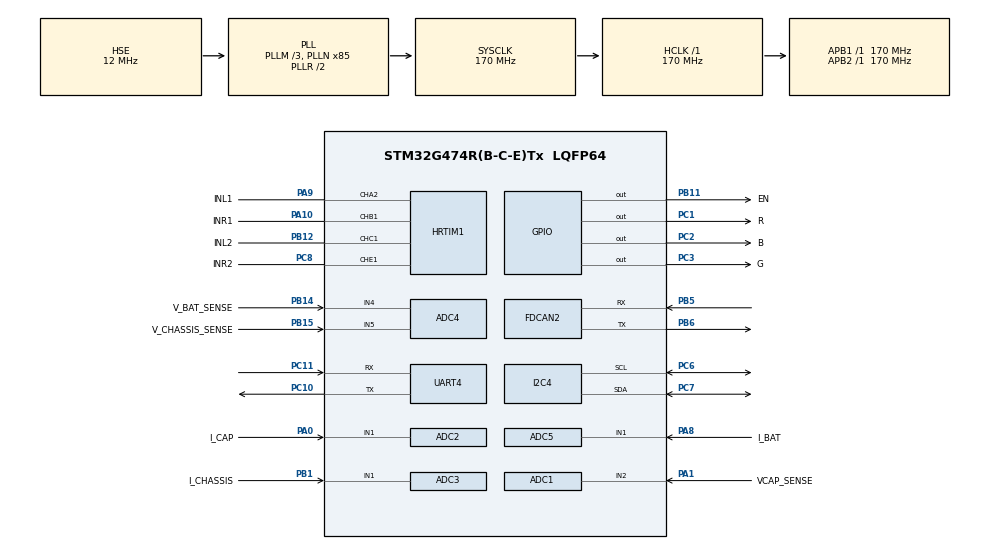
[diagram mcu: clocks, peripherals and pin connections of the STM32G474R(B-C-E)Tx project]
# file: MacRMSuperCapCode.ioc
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ADC1.Channel-0\#ChannelRegularConversion=ADC_CHANNEL_2
ADC1.ContinuousConvMode=DISABLE
ADC1.DMAContinuousRequests=ENABLE
ADC1.ExternalTrigConv=ADC_EXTERNALTRIG_HRTIM_TRG1
ADC1.NbrOfConversion=1
ADC1.NbrOfConversionFlag=1
ADC1.OffsetNumber-0\#ChannelRegularConversion=ADC_OFFSET_NONE
ADC1.Rank-0\#ChannelRegularConversion=1
ADC1.SamplingTime-0\#ChannelRegularConversion=ADC_SAMPLETIME_24CYCLES_5
ADC1.master=1
ADC2.Channel-3\#ChannelRegularConversion=ADC_CHANNEL_1
ADC2.DMAContinuousRequests=ENABLE
ADC2.ExternalTrigConv=ADC_EXTERNALTRIG_HRTIM_TRG1
ADC2.NbrOfConversionFlag=1
ADC2.OffsetNumber-3\#ChannelRegularConversion=ADC_OFFSET_NONE
ADC2.Rank-3\#ChannelRegularConversion=1
ADC2.SamplingTime-3\#ChannelRegularConversion=ADC_SAMPLETIME_24CYCLES_5
ADC3.Channel-0\#ChannelRegularConversion=ADC_CHANNEL_1
ADC3.DMAContinuousRequests=ENABLE
ADC3.ExternalTrigConv=ADC_EXTERNALTRIG_HRTIM_TRG1
ADC3.NbrOfConversionFlag=1
ADC3.OffsetNumber-0\#ChannelRegularConversion=ADC_OFFSET_NONE
ADC3.Rank-0\#ChannelRegularConversion=1
ADC3.SamplingTime-0\#ChannelRegularConversion=ADC_SAMPLETIME_24CYCLES_5
ADC3.master=1
ADC4.Channel-0\#ChannelRegularConversion=ADC_CHANNEL_5
ADC4.Channel-1\#ChannelRegularConversion=ADC_CHANNEL_4
ADC4.ContinuousConvMode=DISABLE
ADC4.DMAContinuousRequests=ENABLE
ADC4.DiscontinuousConvMode=ENABLE
ADC4.EOCSelection=ADC_EOC_SEQ_CONV
ADC4.ExternalTrigConv=ADC_EXTERNALTRIG_HRTIM_TRG1
ADC4.NbrOfConversion=2
ADC4.NbrOfConversionFlag=1
ADC4.NbrOfDiscConversion=2
ADC4.OffsetNumber-0\#ChannelRegularConversion=ADC_OFFSET_NONE
ADC4.OffsetNumber-1\#ChannelRegularConversion=ADC_OFFSET_NONE
ADC4.Rank-0\#ChannelRegularConversion=1
ADC4.Rank-1\#ChannelRegularConversion=2
ADC4.SamplingTime-0\#ChannelRegularConversion=ADC_SAMPLETIME_24CYCLES_5
ADC4.SamplingTime-1\#ChannelRegularConversion=ADC_SAMPLETIME_24CYCLES_5
ADC5.Channel-2\#ChannelRegularConversion=ADC_CHANNEL_1
ADC5.DMAContinuousRequests=ENABLE
ADC5.EOCSelection=ADC_EOC_SEQ_CONV
ADC5.ExternalTrigConv=ADC_EXTERNALTRIG_HRTIM_TRG1
ADC5.NbrOfConversion=1
ADC5.NbrOfConversionFlag=1
ADC5.OffsetNumber-2\#ChannelRegularConversion=ADC_OFFSET_NONE
ADC5.Rank-2\#ChannelRegularConversion=1
ADC5.SamplingTime-2\#ChannelRegularConversion=ADC_SAMPLETIME_24CYCLES_5
Dma.ADC1.0.Direction=DMA_PERIPH_TO_MEMORY
Dma.ADC1.0.EventEnable=DISABLE
Dma.ADC1.0.Instance=DMA1_Channel1
Dma.ADC1.0.MemDataAlignment=DMA_MDATAALIGN_HALFWORD
Dma.ADC1.0.MemInc=DMA_MINC_ENABLE
Dma.ADC1.0.Mode=DMA_CIRCULAR
Dma.ADC1.0.PeriphDataAlignment=DMA_PDATAALIGN_HALFWORD
Dma.ADC1.0.PeriphInc=DMA_PINC_DISABLE
Dma.ADC1.0.Polarity=HAL_DMAMUX_REQ_GEN_RISING
Dma.ADC1.0.Priority=DMA_PRIORITY_LOW
Dma.ADC1.0.RequestNumber=1
Dma.ADC1.0.SignalID=NONE
Dma.ADC1.0.SyncEnable=DISABLE
Dma.ADC1.0.SyncPolarity=HAL_DMAMUX_SYNC_NO_EVENT
Dma.ADC1.0.SyncRequestNumber=1
Dma.ADC1.0.SyncSignalID=NONE
Dma.ADC2.1.Direction=DMA_PERIPH_TO_MEMORY
Dma.ADC2.1.EventEnable=DISABLE
Dma.ADC2.1.Instance=DMA1_Channel2
Dma.ADC2.1.MemDataAlignment=DMA_MDATAALIGN_HALFWORD
Dma.ADC2.1.MemInc=DMA_MINC_ENABLE
Dma.ADC2.1.Mode=DMA_CIRCULAR
Dma.ADC2.1.PeriphDataAlignment=DMA_PDATAALIGN_HALFWORD
Dma.ADC2.1.PeriphInc=DMA_PINC_DISABLE
Dma.ADC2.1.Polarity=HAL_DMAMUX_REQ_GEN_RISING
Dma.ADC2.1.Priority=DMA_PRIORITY_LOW
Dma.ADC2.1.RequestNumber=1
Dma.ADC2.1.SignalID=NONE
Dma.ADC2.1.SyncEnable=DISABLE
Dma.ADC2.1.SyncPolarity=HAL_DMAMUX_SYNC_NO_EVENT
Dma.ADC2.1.SyncRequestNumber=1
Dma.ADC2.1.SyncSignalID=NONE
Dma.ADC3.2.Direction=DMA_PERIPH_TO_MEMORY
Dma.ADC3.2.EventEnable=DISABLE
Dma.ADC3.2.Instance=DMA1_Channel3
Dma.ADC3.2.MemDataAlignment=DMA_MDATAALIGN_HALFWORD
Dma.ADC3.2.MemInc=DMA_MINC_ENABLE
Dma.ADC3.2.Mode=DMA_CIRCULAR
Dma.ADC3.2.PeriphDataAlignment=DMA_PDATAALIGN_HALFWORD
Dma.ADC3.2.PeriphInc=DMA_PINC_DISABLE
Dma.ADC3.2.Polarity=HAL_DMAMUX_REQ_GEN_RISING
Dma.ADC3.2.Priority=DMA_PRIORITY_LOW
Dma.ADC3.2.RequestNumber=1
Dma.ADC3.2.SignalID=NONE
Dma.ADC3.2.SyncEnable=DISABLE
Dma.ADC3.2.SyncPolarity=HAL_DMAMUX_SYNC_NO_EVENT
Dma.ADC3.2.SyncRequestNumber=1
Dma.ADC3.2.SyncSignalID=NONE
Dma.ADC4.3.Direction=DMA_PERIPH_TO_MEMORY
Dma.ADC4.3.EventEnable=DISABLE
Dma.ADC4.3.Instance=DMA1_Channel4
Dma.ADC4.3.MemDataAlignment=DMA_MDATAALIGN_HALFWORD
Dma.ADC4.3.MemInc=DMA_MINC_ENABLE
Dma.ADC4.3.Mode=DMA_CIRCULAR
Dma.ADC4.3.PeriphDataAlignment=DMA_PDATAALIGN_HALFWORD
Dma.ADC4.3.PeriphInc=DMA_PINC_DISABLE
Dma.ADC4.3.Polarity=HAL_DMAMUX_REQ_GEN_RISING
Dma.ADC4.3.Priority=DMA_PRIORITY_LOW
Dma.ADC4.3.RequestNumber=1
Dma.ADC4.3.SignalID=NONE
Dma.ADC4.3.SyncEnable=DISABLE
Dma.ADC4.3.SyncPolarity=HAL_DMAMUX_SYNC_NO_EVENT
Dma.ADC4.3.SyncRequestNumber=1
Dma.ADC4.3.SyncSignalID=NONE
Dma.ADC5.4.Direction=DMA_PERIPH_TO_MEMORY
Dma.ADC5.4.EventEnable=DISABLE
Dma.ADC5.4.Instance=DMA1_Channel5
Dma.ADC5.4.MemDataAlignment=DMA_MDATAALIGN_HALFWORD
Dma.ADC5.4.MemInc=DMA_MINC_ENABLE
Dma.ADC5.4.Mode=DMA_CIRCULAR
Dma.ADC5.4.PeriphDataAlignment=DMA_PDATAALIGN_HALFWORD
Dma.ADC5.4.PeriphInc=DMA_PINC_DISABLE
Dma.ADC5.4.Polarity=HAL_DMAMUX_REQ_GEN_RISING
Dma.ADC5.4.Priority=DMA_PRIORITY_LOW
Dma.ADC5.4.RequestNumber=1
Dma.ADC5.4.SignalID=NONE
Dma.ADC5.4.SyncEnable=DISABLE
Dma.ADC5.4.SyncPolarity=HAL_DMAMUX_SYNC_NO_EVENT
Dma.ADC5.4.SyncRequestNumber=1
Dma.ADC5.4.SyncSignalID=NONE
Dma.Request0=ADC1
Dma.Request1=ADC2
Dma.Request2=ADC3
Dma.Request3=ADC4
Dma.Request4=ADC5
Dma.Request5=UART4_TX
Dma.UART4_TX.5.Direction=DMA_MEMORY_TO_PERIPH
Dma.UART4_TX.5.EventEnable=DISABLE
Dma.UART4_TX.5.Instance=DMA1_Channel7
Dma.UART4_TX.5.MemDataAlignment=DMA_MDATAALIGN_BYTE
Dma.UART4_TX.5.MemInc=DMA_MINC_ENABLE
Dma.UART4_TX.5.Mode=DMA_NORMAL
Dma.UART4_TX.5.PeriphDataAlignment=DMA_PDATAALIGN_BYTE
Dma.UART4_TX.5.PeriphInc=DMA_PINC_DISABLE
Dma.UART4_TX.5.Polarity=HAL_DMAMUX_REQ_GEN_RISING
Dma.UART4_TX.5.Priority=DMA_PRIORITY_LOW
Dma.UART4_TX.5.RequestNumber=1
Dma.UART4_TX.5.SignalID=NONE
Dma.UART4_TX.5.SyncEnable=DISABLE
Dma.UART4_TX.5.SyncPolarity=HAL_DMAMUX_SYNC_NO_EVENT
Dma.UART4_TX.5.SyncRequestNumber=1
Dma.UART4_TX.5.SyncSignalID=NONE
FDCAN2.CalculateBaudRateNominal=1000000
FDCAN2.CalculateTimeBitNominal=1000
FDCAN2.CalculateTimeQuantumNominal=100.0
FDCAN2.DataPrescaler=17
FDCAN2.DataSyncJumpWidth=4
FDCAN2.DataTimeSeg1=5
FDCAN2.DataTimeSeg2=4
FDCAN2.ExtFiltersNbr=8
FDCAN2.NominalPrescaler=17
FDCAN2.NominalSyncJumpWidth=4
FDCAN2.NominalTimeSeg1=5
FDCAN2.NominalTimeSeg2=4
FDCAN2.StdFiltersNbr=28
HRTIM1.ADCTrigger1_Source1=HRTIM_ADCTRIGGEREVENT13_MASTER_PERIOD
HRTIM1.ADCTrigger_Id1=HRTIM_ADCTRIGGER_1
HRTIM1.BurstDMAconfig-MasterTimer=__NULL
HRTIM1.CompareUnit1-MasterTimer=HRTIM_COMPAREUNIT_1
HRTIM1.CompareUnit1-Output_TA2=HRTIM_COMPAREUNIT_1
HRTIM1.CompareUnit1-Output_TB1=HRTIM_COMPAREUNIT_1
HRTIM1.CompareUnit1-Output_TC1=HRTIM_COMPAREUNIT_1
HRTIM1.CompareUnit1-Output_TE1=HRTIM_COMPAREUNIT_1
HRTIM1.CompareUnit2-MasterTimer=HRTIM_COMPAREUNIT_2
HRTIM1.CompareUnit3-MasterTimer=HRTIM_COMPAREUNIT_3
HRTIM1.CompareUnit4-MasterTimer=HRTIM_COMPAREUNIT_4
HRTIM1.CompareValue1-MasterTimer=13600
HRTIM1.CompareValue2-MasterTimer=13600
HRTIM1.CompareValue3-MasterTimer=13600
HRTIM1.CompareValue4-MasterTimer=13600
HRTIM1.InterruptRequests1_Master=HRTIM_MASTER_IT_MREP
HRTIM1.ModeTimeBase-Output_TA2=HRTIM_MODE_SINGLESHOT_RETRIGGERABLE
HRTIM1.ModeTimeBase-Output_TB1=HRTIM_MODE_SINGLESHOT_RETRIGGERABLE
HRTIM1.ModeTimeBase-Output_TC1=HRTIM_MODE_SINGLESHOT_RETRIGGERABLE
HRTIM1.ModeTimeBase-Output_TE1=HRTIM_MODE_SINGLESHOT_RETRIGGERABLE
HRTIM1.NumberADCTriggerSource1=1
HRTIM1.NumberInterruptRequests_Master-MasterTimer=1
HRTIM1.NumberResetSource1-Output_TB1=1
HRTIM1.NumberResetSource1-Output_TC1=1
HRTIM1.NumberResetSource1-Output_TE1=1
HRTIM1.NumberResetSource2-Output_TA2=1
HRTIM1.NumberResetTrigger-Output_TA2=1
HRTIM1.NumberResetTrigger-Output_TB1=1
HRTIM1.NumberResetTrigger-Output_TC1=1
HRTIM1.NumberResetTrigger-Output_TE1=1
HRTIM1.NumberSetSource1-Output_TB1=1
HRTIM1.NumberSetSource1-Output_TC1=1
HRTIM1.NumberSetSource1-Output_TE1=1
HRTIM1.NumberSetSource2-Output_TA2=1
HRTIM1.Periode_MASTER=13600
HRTIM1.Periode_TA=27200
HRTIM1.Periode_TB=27200
HRTIM1.Periode_TC=27200
HRTIM1.Periode_TE=27200
HRTIM1.PreloadEnable-MasterTimer=HRTIM_PRELOAD_ENABLED
HRTIM1.PreloadEnable-Output_TA2=HRTIM_PRELOAD_ENABLED
HRTIM1.PreloadEnable-Output_TB1=HRTIM_PRELOAD_ENABLED
HRTIM1.PreloadEnable-Output_TC1=HRTIM_PRELOAD_ENABLED
HRTIM1.PreloadEnable-Output_TE1=HRTIM_PRELOAD_ENABLED
HRTIM1.PrescalerRatio_TA=HRTIM_PRESCALERRATIO_MUL32
HRTIM1.RepetitionUpdate-MasterTimer=HRTIM_UPDATEONREPETITION_ENABLED
HRTIM1.RepetitionUpdate-Output_TA2=HRTIM_UPDATEONREPETITION_ENABLED
HRTIM1.RepetitionUpdate-Output_TB1=HRTIM_UPDATEONREPETITION_ENABLED
HRTIM1.RepetitionUpdate-Output_TC1=HRTIM_UPDATEONREPETITION_ENABLED
HRTIM1.RepetitionUpdate-Output_TE1=HRTIM_UPDATEONREPETITION_ENABLED
HRTIM1.ResetOutput1_Source1-Output_TB1=HRTIM_OUTPUTRESET_TIMCMP1
HRTIM1.ResetOutput1_Source1-Output_TC1=HRTIM_OUTPUTRESET_TIMCMP1
HRTIM1.ResetOutput1_Source1-Output_TE1=HRTIM_OUTPUTRESET_TIMCMP1
HRTIM1.ResetOutput2_Source1-Output_TA2=HRTIM_OUTPUTRESET_TIMCMP1
HRTIM1.ResetTrigger1-Output_TA2=HRTIM_TIMRESETTRIGGER_MASTER_CMP1
HRTIM1.ResetTrigger1-Output_TB1=HRTIM_TIMRESETTRIGGER_MASTER_CMP2
HRTIM1.ResetTrigger1-Output_TC1=HRTIM_TIMRESETTRIGGER_MASTER_CMP3
HRTIM1.ResetTrigger1-Output_TE1=HRTIM_TIMRESETTRIGGER_MASTER_CMP4
HRTIM1.ResetUpdate-Output_TA2=HRTIM_TIMUPDATEONRESET_ENABLED
HRTIM1.ResetUpdate-Output_TB1=HRTIM_TIMUPDATEONRESET_ENABLED
HRTIM1.ResetUpdate-Output_TC1=HRTIM_TIMUPDATEONRESET_ENABLED
HRTIM1.ResetUpdate-Output_TE1=HRTIM_TIMUPDATEONRESET_ENABLED
HRTIM1.SetOutput1_Source1-Output_TB1=HRTIM_OUTPUTSET_MASTERCMP2
HRTIM1.SetOutput1_Source1-Output_TC1=HRTIM_OUTPUTSET_MASTERCMP3
HRTIM1.SetOutput1_Source1-Output_TE1=HRTIM_OUTPUTSET_MASTERCMP4
HRTIM1.SetOutput2_Source1-Output_TA2=HRTIM_OUTPUTSET_MASTERCMP1
I2C4.Timing=0x40B285C2
IWDG.Reload=2047
IWDG.Window=2047
Mcu.Family=STM32G4
Mcu.Name=STM32G474R(B-C-E)Tx
Mcu.Package=LQFP64
NVIC.FDCAN2_IT0_IRQn=true\:0\:0\:false\:false\:true\:true\:true\:true
NVIC.HRTIM1_Master_IRQn=true\:1\:0\:true\:false\:true\:true\:true\:true
NVIC.PriorityGroup=NVIC_PRIORITYGROUP_4
NVIC.UART4_IRQn=true\:0\:0\:false\:false\:true\:true\:true\:true
PA0.GPIO_Label=I_CAP
PA0.Mode=IN1-Single-Ended
PA0.Signal=ADC2_IN1
PA1.GPIO_Label=VCAP_SENSE
PA1.Mode=IN2-Single-Ended
PA1.Signal=ADC1_IN2
PA10.GPIO_Label=INR1
PA10.GPIO_Speed_High_Default=GPIO_SPEED_FREQ_MEDIUM
PA10.Mode=Output_TB1
PA10.Signal=HRTIM1_CHB1
PA13.Mode=Serial_Wire
PA13.Signal=SYS_JTMS-SWDIO
PA14.Mode=Serial_Wire
PA14.Signal=SYS_JTCK-SWCLK
PA8.GPIO_Label=I_BAT
PA8.Mode=IN1-Single-Ended
PA8.Signal=ADC5_IN1
PA9.GPIO_Label=INL1
PA9.GPIO_Speed_High_Default=GPIO_SPEED_FREQ_MEDIUM
PA9.Mode=Output_TA2
PA9.Signal=HRTIM1_CHA2
PB1.GPIO_Label=I_CHASSIS
PB1.Mode=IN1-Single-Ended
PB1.Signal=ADC3_IN1
PB11.GPIO_Label=EN
PB11.Signal=GPIO_Output
PB12.GPIO_Label=INL2
PB12.GPIO_Speed_High_Default=GPIO_SPEED_FREQ_MEDIUM
PB12.Mode=Output_TC1
PB12.Signal=HRTIM1_CHC1
PB14.GPIO_Label=V_BAT_SENSE
PB14.Mode=IN4-Single-Ended
PB14.Signal=ADC4_IN4
PB15.GPIO_Label=V_CHASSIS_SENSE
PB15.Mode=IN5-Single-Ended
PB15.Signal=ADC4_IN5
PB5.Mode=FDCAN_Activate
PB5.Signal=FDCAN2_RX
PB6.Mode=FDCAN_Activate
PB6.Signal=FDCAN2_TX
PC1.GPIO_Label=R
PC1.PinState=GPIO_PIN_RESET
PC1.Signal=GPIO_Output
PC10.Mode=Asynchronous
PC10.Signal=UART4_TX
PC11.Mode=Asynchronous
PC11.Signal=UART4_RX
PC2.GPIO_Label=B
PC2.PinState=GPIO_PIN_RESET
PC2.Signal=GPIO_Output
PC3.GPIO_Label=G
PC3.PinState=GPIO_PIN_RESET
PC3.Signal=GPIO_Output
PC6.Mode=I2C
PC6.Signal=I2C4_SCL
PC7.Mode=I2C
PC7.Signal=I2C4_SDA
PC8.GPIO_Label=INR2
PC8.GPIO_Speed_High_Default=GPIO_SPEED_FREQ_MEDIUM
PC8.Mode=Output_TE1
PC8.Signal=HRTIM1_CHE1
PF0-OSC_IN.Mode=HSE-External-Oscillator
PF0-OSC_IN.Signal=RCC_OSC_IN
PF1-OSC_OUT.Mode=HSE-External-Oscillator
PF1-OSC_OUT.Signal=RCC_OSC_OUT
ProjectManager.HeapSize=0x200
ProjectManager.StackSize=0x400
ProjectManager.TargetToolchain=Makefile
RCC.ADC12Freq_Value=170000000
RCC.ADC345Freq_Value=170000000
RCC.AHBFreq_Value=170000000
RCC.APB1Freq_Value=170000000
RCC.APB1TimFreq_Value=170000000
RCC.APB2Freq_Value=170000000
RCC.APB2TimFreq_Value=170000000
RCC.CortexFreq_Value=170000000
RCC.EXTERNAL_CLOCK_VALUE=12288000
RCC.HCLKFreq_Value=170000000
RCC.HSE_VALUE=12000000
RCC.HSI48_VALUE=48000000
RCC.HSI_VALUE=16000000
RCC.LSE_VALUE=32768
RCC.PLLM=RCC_PLLM_DIV3
RCC.PLLN=85
RCC.PLLSourceVirtual=RCC_PLLSOURCE_HSE
RCC.SYSCLKFreq_VALUE=170000000
RCC.SYSCLKSource=RCC_SYSCLKSOURCE_PLLCLK
RCC.USBFreq_Value=170000000
RCC.VCOOutputFreq_Value=340000000
VP_HRTIM1_VS_hrtimMasterTimerNoOutput.Mode=MasterTimer
VP_IWDG_VS_IWDG.Mode=IWDG_Activate
VP_SYS_VS_DBSignals.Mode=DisableDeadBatterySignals
VP_SYS_V_VREFBUF.Mode=ExternalMode
board=custom

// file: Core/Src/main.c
/* USER CODE BEGIN Header */
/**
  ******************************************************************************
  * @file           : main.c
  * @brief          : Main program body
  ******************************************************************************
  * @attention
  *
  * Copyright (c) 2025 STMicroelectronics.
  * All rights reserved.
  *
  * This software is licensed under terms that can be found in the LICENSE file
  * in the root directory of this software component.
  * If no LICENSE file comes with this software, it is provided AS-IS.
  *
  ******************************************************************************
  */
/* USER CODE END Header */
#include "main.h"
#include "adc.h"
#include "dma.h"
#include "fdcan.h"
#include "hrtim.h"
#include "i2c.h"
#include "iwdg.h"
#include "usart.h"
#include "gpio.h"

/* USER CODE BEGIN Includes */
#include "pwm_ctrl.h"
#include "cap_can.h"

/* USER CODE END Includes */

void SystemClock_Config(void);

int main(void)
{

  /* MCU Configuration--------------------------------------------------------*/

  /* Reset of all peripherals, Initializes the Flash interface and the Systick. */
  HAL_Init();

  /* Configure the system clock */
  SystemClock_Config();

  /* Initialize all configured peripherals */
  MX_GPIO_Init();
  MX_DMA_Init();
  MX_ADC2_Init();
  MX_ADC5_Init();
  MX_FDCAN2_Init();
  MX_HRTIM1_Init();
  MX_I2C4_Init();
  MX_UART4_Init();
  MX_ADC1_Init();
  MX_ADC3_Init();
  MX_ADC4_Init();
  MX_IWDG_Init();
  /* USER CODE BEGIN 2 */
  HAL_IWDG_Refresh(&hiwdg);
  PWM_Init();
  HAL_IWDG_Refresh(&hiwdg);
  LL_HRTIM_TIM_CounterEnable(HRTIM1, LL_HRTIM_TIMER_ALL);
  fdcan2_config();
  /* USER CODE END 2 */

  /* Infinite loop */
  /* USER CODE BEGIN WHILE */
  while (1)
  {
    //can transmit
    //fdcan2_config();
    cap_transmit();
    HAL_Delay(10);
    //send_uart();
    /* USER CODE END WHILE */

  }
}

void SystemClock_Config(void)
{
  RCC_OscInitTypeDef RCC_OscInitStruct = {0};
  RCC_ClkInitTypeDef RCC_ClkInitStruct = {0};

  /** Configure the main internal regulator output voltage
  */
  HAL_PWREx_ControlVoltageScaling(PWR_REGULATOR_VOLTAGE_SCALE1_BOOST);

  /** Initializes the RCC Oscillators according to the specified parameters
  * in the RCC_OscInitTypeDef structure.
  */
  RCC_OscInitStruct.OscillatorType = RCC_OSCILLATORTYPE_LSI|RCC_OSCILLATORTYPE_HSE;
  RCC_OscInitStruct.HSEState = RCC_HSE_ON;
  RCC_OscInitStruct.LSIState = RCC_LSI_ON;
  RCC_OscInitStruct.PLL.PLLState = RCC_PLL_ON;
  RCC_OscInitStruct.PLL.PLLSource = RCC_PLLSOURCE_HSE;
  RCC_OscInitStruct.PLL.PLLM = RCC_PLLM_DIV3;
  RCC_OscInitStruct.PLL.PLLN = 85;
  RCC_OscInitStruct.PLL.PLLP = RCC_PLLP_DIV2;
  RCC_OscInitStruct.PLL.PLLQ = RCC_PLLQ_DIV2;
  RCC_OscInitStruct.PLL.PLLR = RCC_PLLR_DIV2;
  if (HAL_RCC_OscConfig(&RCC_OscInitStruct) != HAL_OK)
  {
    Error_Handler();
  }

  /** Initializes the CPU, AHB and APB buses clocks
  */
  RCC_ClkInitStruct.ClockType = RCC_CLOCKTYPE_HCLK|RCC_CLOCKTYPE_SYSCLK
                              |RCC_CLOCKTYPE_PCLK1|RCC_CLOCKTYPE_PCLK2;
  RCC_ClkInitStruct.SYSCLKSource = RCC_SYSCLKSOURCE_PLLCLK;
  RCC_ClkInitStruct.AHBCLKDivider = RCC_SYSCLK_DIV1;
  RCC_ClkInitStruct.APB1CLKDivider = RCC_HCLK_DIV1;
  RCC_ClkInitStruct.APB2CLKDivider = RCC_HCLK_DIV1;

  if (HAL_RCC_ClockConfig(&RCC_ClkInitStruct, FLASH_LATENCY_4) != HAL_OK)
  {
    Error_Handler();
  }
}

void Error_Handler(void)
{
  /* USER CODE BEGIN Error_Handler_Debug */
  /* User can add his own implementation to report the HAL error return state */
  __disable_irq();
  while (1)
  {
    return;
  }
  /* USER CODE END Error_Handler_Debug */
}
